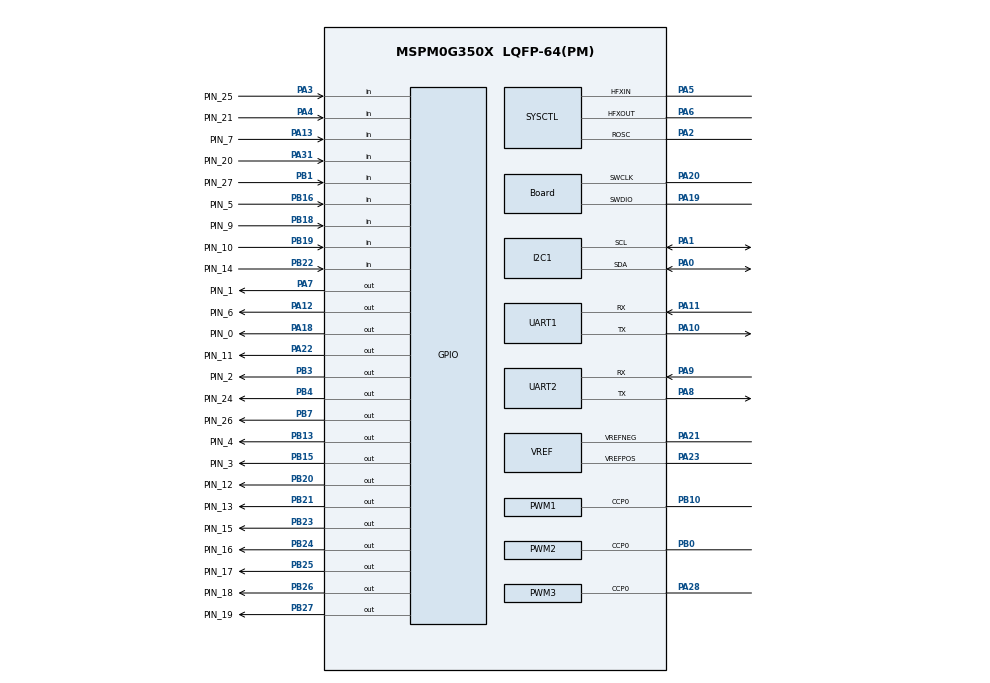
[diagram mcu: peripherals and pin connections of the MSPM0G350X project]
/**
 * @cliArgs --device "MSPM0G350X" --part "Default" --package "LQFP-64(PM)" --product "mspm0_sdk@2.01.00.03"
 * @versions {"tool":"1.21.1+3772"}
 */

/**
 * Import the modules used in this configuration.
 */
const ADC12         = scripting.addModule("/ti/driverlib/ADC12", {}, false);
const ADC121        = ADC12.addInstance();
const ADC122        = ADC12.addInstance();
const Board         = scripting.addModule("/ti/driverlib/Board");
const GPIO          = scripting.addModule("/ti/driverlib/GPIO", {}, false);
const GPIO1         = GPIO.addInstance();
const GPIO2         = GPIO.addInstance();
const GPIO3         = GPIO.addInstance();
const GPIO4         = GPIO.addInstance();
const GPIO5         = GPIO.addInstance();
const GPIO6         = GPIO.addInstance();
const GPIO7         = GPIO.addInstance();
const GPIO8         = GPIO.addInstance();
const GPIO9         = GPIO.addInstance();
const GPIO10        = GPIO.addInstance();
const GPIO11        = GPIO.addInstance();
const GPIO12        = GPIO.addInstance();
const GPIO13        = GPIO.addInstance();
const GPIO14        = GPIO.addInstance();
const GPIO15        = GPIO.addInstance();
const GPIO16        = GPIO.addInstance();
const GPIO17        = GPIO.addInstance();
const GPIO18        = GPIO.addInstance();
const GPIO19        = GPIO.addInstance();
const GPIO20        = GPIO.addInstance();
const GPIO21        = GPIO.addInstance();
const GPIO22        = GPIO.addInstance();
const GPIO23        = GPIO.addInstance();
const GPIO24        = GPIO.addInstance();
const GPIO25        = GPIO.addInstance();
const I2C           = scripting.addModule("/ti/driverlib/I2C", {}, false);
const I2C1          = I2C.addInstance();
const PWM           = scripting.addModule("/ti/driverlib/PWM", {}, false);
const PWM1          = PWM.addInstance();
const PWM2          = PWM.addInstance();
const PWM3          = PWM.addInstance();
const SYSCTL        = scripting.addModule("/ti/driverlib/SYSCTL");
const SYSTICK       = scripting.addModule("/ti/driverlib/SYSTICK");
const UART          = scripting.addModule("/ti/driverlib/UART", {}, false);
const UART1         = UART.addInstance();
const UART2         = UART.addInstance();
const VREF          = scripting.addModule("/ti/driverlib/VREF");
const ProjectConfig = scripting.addModule("/ti/project_config/ProjectConfig");

/**
 * Write custom configuration values to the imported modules.
 */
ADC121.enableDMA                         = false;
ADC121.samplingOperationMode             = "sequence";
ADC121.resolution                        = "DL_ADC12_SAMP_CONV_RES_8_BIT";
ADC121.sampClkDiv                        = "DL_ADC12_CLOCK_DIVIDE_2";
ADC121.sampClkSrc                        = "DL_ADC12_CLOCK_ULPCLK";
ADC121.sampleTime0                       = "875ns";
ADC121.adcMem3chansel                    = "DL_ADC12_INPUT_CHAN_3";
ADC121.adcMem4chansel                    = "DL_ADC12_INPUT_CHAN_4";
ADC121.adcMem5chansel                    = "DL_ADC12_INPUT_CHAN_5";
ADC121.adcMem6chansel                    = "DL_ADC12_INPUT_CHAN_6";
ADC121.adcMem7chansel                    = "DL_ADC12_INPUT_CHAN_7";
ADC121.$name                             = "ADC0";
ADC121.adcMem1_name                      = "CCS_PP";
ADC121.adcMem1chansel                    = "DL_ADC12_INPUT_CHAN_2";
ADC121.adcMem0_name                      = "CCS_CP_FB";
ADC121.endAdd                            = 3;
ADC121.adcMem2_name                      = "GBT_DP1";
ADC121.adcMem2chansel                    = "DL_ADC12_INPUT_CHAN_1";
ADC121.adcMem3_name                      = "PL_FB";
ADC121.peripheral.$assign                = "ADC0";
ADC121.peripheral.adcPin0.$assign        = "PA27";
ADC121.peripheral.adcPin2.$assign        = "PA25";
ADC121.peripheral.adcPin3.$assign        = "PA24";
ADC121.peripheral.adcPin1.$assign        = "PA26";
ADC121.adcPin0Config.hideOutputInversion = scripting.forceWrite(false);
ADC121.adcPin0Config.$name               = "ti_driverlib_gpio_GPIOPinGeneric2";
ADC121.adcPin2Config.$name               = "ti_driverlib_gpio_GPIOPinGeneric3";
ADC121.adcPin3Config.$name               = "ti_driverlib_gpio_GPIOPinGeneric5";
ADC121.adcPin1Config.$name               = "ti_driverlib_gpio_GPIOPinGeneric6";

ADC122.samplingOperationMode             = "sequence";
ADC122.adcMem1chansel                    = "DL_ADC12_INPUT_CHAN_1";
ADC122.adcMem2chansel                    = "DL_ADC12_INPUT_CHAN_2";
ADC122.adcMem0_name                      = "Temp1";
ADC122.adcMem1_name                      = "Temp2";
ADC122.adcMem2_name                      = "Temp3";
ADC122.adcMem3_name                      = "Temp4";
ADC122.adcMem3chansel                    = "DL_ADC12_INPUT_CHAN_4";
ADC122.$name                             = "ADC1_Temp";
ADC122.endAdd                            = 1;
ADC122.peripheral.adcPin0.$assign        = "PA15";
ADC122.peripheral.adcPin1.$assign        = "PA16";
ADC122.adcPin0Config.hideOutputInversion = scripting.forceWrite(false);
ADC122.adcPin0Config.$name               = "ti_driverlib_gpio_GPIOPinGeneric7";
ADC122.adcPin1Config.hideOutputInversion = scripting.forceWrite(false);
ADC122.adcPin1Config.$name               = "ti_driverlib_gpio_GPIOPinGeneric8";

Board.configureVDDA               = true;
Board.peripheral.$assign          = "DEBUGSS";
Board.peripheral.swclkPin.$assign = "PA20";
Board.peripheral.swdioPin.$assign = "PA19";

GPIO1.$name                         = "BSL";
GPIO1.associatedPins[0].$name       = "PIN_0";
GPIO1.associatedPins[0].pin.$assign = "PA18";

GPIO2.$name                         = "LED";
GPIO2.associatedPins[0].$name       = "PIN_1";
GPIO2.associatedPins[0].pin.$assign = "PA7";

GPIO3.$name                         = "EN_Charging";
GPIO3.associatedPins[0].$name       = "PIN_2";
GPIO3.associatedPins[0].pin.$assign = "PB3";

GPIO4.$name                         = "REQ_Charge";
GPIO4.associatedPins[0].$name       = "PIN_3";
GPIO4.associatedPins[0].pin.$assign = "PB15";

GPIO5.$name                         = "IO_Out_2";
GPIO5.associatedPins[0].$name       = "PIN_4";
GPIO5.associatedPins[0].pin.$assign = "PB13";

GPIO6.$name                         = "IO_IN_1";
GPIO6.associatedPins[0].$name       = "PIN_5";
GPIO6.associatedPins[0].direction   = "INPUT";
GPIO6.associatedPins[0].pin.$assign = "PB16";

GPIO7.$name                         = "IO_Out_1";
GPIO7.associatedPins[0].$name       = "PIN_6";
GPIO7.associatedPins[0].pin.$assign = "PA12";

GPIO8.$name                         = "IO_IN_2";
GPIO8.associatedPins[0].$name       = "PIN_7";
GPIO8.associatedPins[0].direction   = "INPUT";
GPIO8.associatedPins[0].pin.$assign = "PA13";

GPIO9.$name                         = "CdM_j";
GPIO9.associatedPins[0].$name       = "PIN_9";
GPIO9.associatedPins[0].direction   = "INPUT";
GPIO9.associatedPins[0].pin.$assign = "PB18";

GPIO10.$name                         = "CdM_PD";
GPIO10.associatedPins[0].$name       = "PIN_10";
GPIO10.associatedPins[0].direction   = "INPUT";
GPIO10.associatedPins[0].pin.$assign = "PB19";

GPIO11.$name                         = "CdM_d2";
GPIO11.associatedPins[0].$name       = "PIN_11";
GPIO11.associatedPins[0].pin.$assign = "PA22";

GPIO12.$name                         = "CdM_d1";
GPIO12.associatedPins[0].$name       = "PIN_12";
GPIO12.associatedPins[0].pin.$assign = "PB20";

GPIO13.$name                         = "GBT_EV_S2";
GPIO13.associatedPins[0].$name       = "PIN_13";
GPIO13.associatedPins[0].pin.$assign = "PB21";

GPIO14.$name                         = "Pluck_Lock_CdM_FB";
GPIO14.associatedPins[0].$name       = "PIN_14";
GPIO14.associatedPins[0].direction   = "INPUT";
GPIO14.associatedPins[0].pin.$assign = "PB22";

GPIO15.$name                         = "GBT_EV_S2apo";
GPIO15.associatedPins[0].$name       = "PIN_15";
GPIO15.associatedPins[0].pin.$assign = "PB23";

GPIO16.$name                         = "GBT_S1";
GPIO16.associatedPins[0].$name       = "PIN_16";
GPIO16.associatedPins[0].pin.$assign = "PB24";

GPIO17.$name                         = "GBT_S0";
GPIO17.associatedPins[0].$name       = "PIN_17";
GPIO17.associatedPins[0].pin.$assign = "PB25";

GPIO18.$name                         = "Pluck_Lock_nSleep";
GPIO18.associatedPins[0].$name       = "PIN_18";
GPIO18.associatedPins[0].pin.$assign = "PB26";

GPIO19.$name                         = "Pluck_Lock_Direction";
GPIO19.associatedPins[0].$name       = "PIN_19";
GPIO19.associatedPins[0].pin.$assign = "PB27";

GPIO20.$name                         = "R_Mirror_Out";
GPIO20.associatedPins[0].$name       = "PIN_20";
GPIO20.associatedPins[0].direction   = "INPUT";
GPIO20.associatedPins[0].pin.$assign = "PA31";

GPIO21.$name                         = "Relay_Check";
GPIO21.associatedPins[0].$name       = "PIN_21";
GPIO21.associatedPins[0].direction   = "INPUT";
GPIO21.associatedPins[0].pin.$assign = "PA4";

GPIO22.$name                         = "RCD_Reset";
GPIO22.associatedPins[0].$name       = "PIN_24";
GPIO22.associatedPins[0].pin.$assign = "PB4";

GPIO23.$name                         = "Super_Cap_Char";
GPIO23.associatedPins[0].$name       = "PIN_25";
GPIO23.associatedPins[0].direction   = "INPUT";
GPIO23.associatedPins[0].pin.$assign = "PA3";

GPIO24.$name                         = "IO_Out_3";
GPIO24.associatedPins[0].$name       = "PIN_26";
GPIO24.associatedPins[0].pin.$assign = "PB7";

GPIO25.$name                         = "RCD_nFault";
GPIO25.associatedPins[0].$name       = "PIN_27";
GPIO25.associatedPins[0].direction   = "INPUT";
GPIO25.associatedPins[0].pin.$assign = "PB1";

I2C1.$name                             = "RCD";
I2C1.basicEnableController             = true;
I2C1.advControllerRXFIFOTRIG           = "BYTES_8";
I2C1.advControllerTXFIFOTRIG           = "BYTES_7";
I2C1.advDigitalGlitchFilter            = "CLOCKS_1";
I2C1.enableDMAEvent1                   = false;
I2C1.enableDMAEvent2                   = false;
I2C1.peripheral.$assign                = "I2C0";
I2C1.peripheral.sdaPin.$assign         = "PA0";
I2C1.peripheral.sclPin.$assign         = "PA1";
I2C1.sdaPinConfig.hideOutputInversion  = scripting.forceWrite(false);
I2C1.sdaPinConfig.onlyInternalResistor = scripting.forceWrite(false);
I2C1.sdaPinConfig.passedPeripheralType = scripting.forceWrite("Digital");
I2C1.sdaPinConfig.$name                = "ti_driverlib_gpio_GPIOPinGeneric16";
I2C1.sclPinConfig.hideOutputInversion  = scripting.forceWrite(false);
I2C1.sclPinConfig.onlyInternalResistor = scripting.forceWrite(false);
I2C1.sclPinConfig.passedPeripheralType = scripting.forceWrite("Digital");
I2C1.sclPinConfig.$name                = "ti_driverlib_gpio_GPIOPinGeneric17";

PWM1.profile                            = "basic_single_channel_center_align";
PWM1.$name                              = "CCS_CP";
PWM1.peripheral.$assign                 = "TIMG0";
PWM1.peripheral.ccp0Pin.$assign         = "PB10";
PWM1.PWM_CHANNEL_0.$name                = "ti_driverlib_pwm_PWMTimerCC0";
PWM1.ccp0PinConfig.$name                = "ti_driverlib_gpio_GPIOPinGeneric4";
PWM1.ccp0PinConfig.direction            = scripting.forceWrite("OUTPUT");
PWM1.ccp0PinConfig.hideOutputInversion  = scripting.forceWrite(false);
PWM1.ccp0PinConfig.onlyInternalResistor = scripting.forceWrite(false);
PWM1.ccp0PinConfig.passedPeripheralType = scripting.forceWrite("Digital");

PWM2.$name                              = "Relay_EN";
PWM2.profile                            = "basic_single_channel_center_align";
PWM2.peripheral.$assign                 = "TIMA1";
PWM2.peripheral.ccp0Pin.$assign         = "PB0";
PWM2.PWM_CHANNEL_0.$name                = "ti_driverlib_pwm_PWMTimerCC1";
PWM2.ccp0PinConfig.direction            = scripting.forceWrite("OUTPUT");
PWM2.ccp0PinConfig.hideOutputInversion  = scripting.forceWrite(false);
PWM2.ccp0PinConfig.onlyInternalResistor = scripting.forceWrite(false);
PWM2.ccp0PinConfig.passedPeripheralType = scripting.forceWrite("Digital");
PWM2.ccp0PinConfig.$name                = "ti_driverlib_gpio_GPIOPinGeneric11";

PWM3.$name                              = "PluckLock";
PWM3.profile                            = "basic_single_channel_center_align";
PWM3.peripheral.$assign                 = "TIMG7";
PWM3.peripheral.ccp0Pin.$assign         = "PA28";
PWM3.PWM_CHANNEL_0.$name                = "ti_driverlib_pwm_PWMTimerCC5";
PWM3.ccp0PinConfig.direction            = scripting.forceWrite("OUTPUT");
PWM3.ccp0PinConfig.hideOutputInversion  = scripting.forceWrite(false);
PWM3.ccp0PinConfig.onlyInternalResistor = scripting.forceWrite(false);
PWM3.ccp0PinConfig.passedPeripheralType = scripting.forceWrite("Digital");
PWM3.ccp0PinConfig.$name                = "ti_driverlib_gpio_GPIOPinGeneric15";

SYSCTL.powerPolicy                  = "STOP2";
SYSCTL.useHFCLK_Manual              = true;
SYSCTL.HFCLKSource                  = "HFXT";
SYSCTL.CANCLKSource                 = "SYSPLLCLK1";
SYSCTL.SYSPLL_CLK1En                = true;
SYSCTL.forceDefaultClkConfig        = true;
SYSCTL.HFCLK_Freq                   = 40000000;
SYSCTL.enableROSC                   = true;
SYSCTL.enableSYSOSCFCL              = true;
SYSCTL.peripheral.hfxInPin.$assign  = "PA5";
SYSCTL.peripheral.hfxOutPin.$assign = "PA6";
SYSCTL.peripheral.roscPin.$assign   = "PA2";

UART1.$name                            = "AM62L";
UART1.peripheral.$assign               = "UART0";
UART1.peripheral.rxPin.$assign         = "PA11";
UART1.peripheral.txPin.$assign         = "PA10";
UART1.txPinConfig.direction            = scripting.forceWrite("OUTPUT");
UART1.txPinConfig.hideOutputInversion  = scripting.forceWrite(false);
UART1.txPinConfig.onlyInternalResistor = scripting.forceWrite(false);
UART1.txPinConfig.passedPeripheralType = scripting.forceWrite("Digital");
UART1.txPinConfig.$name                = "ti_driverlib_gpio_GPIOPinGeneric0";
UART1.rxPinConfig.hideOutputInversion  = scripting.forceWrite(false);
UART1.rxPinConfig.onlyInternalResistor = scripting.forceWrite(false);
UART1.rxPinConfig.passedPeripheralType = scripting.forceWrite("Digital");
UART1.rxPinConfig.$name                = "ti_driverlib_gpio_GPIOPinGeneric1";

UART2.$name                            = "Debug";
UART2.peripheral.$assign               = "UART1";
UART2.peripheral.rxPin.$assign         = "PA9";
UART2.peripheral.txPin.$assign         = "PA8";
UART2.txPinConfig.direction            = scripting.forceWrite("OUTPUT");
UART2.txPinConfig.hideOutputInversion  = scripting.forceWrite(false);
UART2.txPinConfig.onlyInternalResistor = scripting.forceWrite(false);
UART2.txPinConfig.passedPeripheralType = scripting.forceWrite("Digital");
UART2.txPinConfig.$name                = "ti_driverlib_gpio_GPIOPinGeneric19";
UART2.rxPinConfig.hideOutputInversion  = scripting.forceWrite(false);
UART2.rxPinConfig.onlyInternalResistor = scripting.forceWrite(false);
UART2.rxPinConfig.passedPeripheralType = scripting.forceWrite("Digital");
UART2.rxPinConfig.$name                = "ti_driverlib_gpio_GPIOPinGeneric20";

VREF.basicMode                     = "DL_VREF_ENABLE_DISABLE";
VREF.basicExtVolt                  = 3.3;
VREF.basicVrefPins                 = "VREF+-";
VREF.peripheral.$assign            = "VREF";
VREF.peripheral.vrefPosPin.$assign = "PA23";
VREF.peripheral.vrefNegPin.$assign = "PA21";
VREF.vrefPosPinConfig.$name        = "ti_driverlib_gpio_GPIOPinGeneric18";
VREF.vrefNegPinConfig.$name        = "ti_driverlib_gpio_GPIOPinGeneric34";

ProjectConfig.deviceSpin = "MSPM0G3507";

/**
 * Pinmux solution for unlocked pins/peripherals. This ensures that minor changes to the automatic solver in a future
 * version of the tool will not impact the pinmux you originally saw.  These lines can be completely deleted in order to
 * re-solve from scratch.
 */
ADC122.peripheral.$suggestSolution = "ADC1";
SYSCTL.peripheral.$suggestSolution = "SYSCTL";
